# tac_sgcp register map
Vendor: Texas Instruments
Peripheral module from a debugger description file (folder Keystone2).
Registers are 32-bit, read-write, no defined reset value unless marked. A register's access mark holds for its fields unless they carry their own. Offsets are as the file gives them; lines under a group give offsets from that group; [hi:lo] are bit positions; {n}, {i} and the like mark numbered series; 'fields as' and 'values as' point back to an identical list; <NAME> marks a mode.

## TAC_SGCP
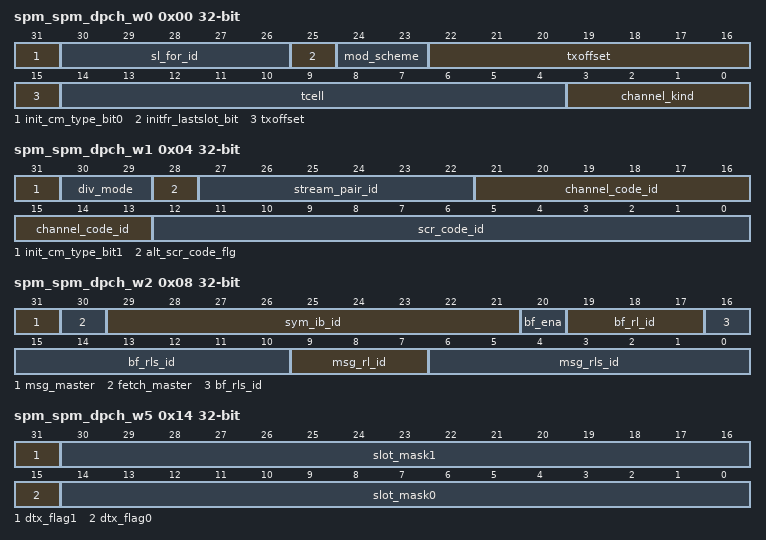
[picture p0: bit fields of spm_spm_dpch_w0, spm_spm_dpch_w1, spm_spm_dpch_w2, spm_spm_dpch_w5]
0x00 spm_spm_dpch_w0 — (1 of 512, stride 32)
  [31] init_cm_type_bit0, [30:26] sl_for_id, [25] initfr_lastslot_bit, [24:23] mod_scheme, [22:15] txoffset, [14:4] tcell, [3:0] channel_kind
0x04 spm_spm_dpch_w1 — (1 of 512, stride 32)
  [31] init_cm_type_bit1, [30:29] div_mode, [28] alt_scr_code_flg, [27:22] stream_pair_id, [21:13] channel_code_id, [12:0] scr_code_id
0x08 spm_spm_dpch_w2 — (1 of 512, stride 32)
  [31] msg_master, [30] fetch_master, [29:21] sym_ib_id, [20] bf_ena, [19:17] bf_rl_id, [16:10] bf_rls_id, [9:7] msg_rl_id, [6:0] msg_rls_id
0x0C spm_spm_dpch_w3 — (1 of 512, stride 32)
  [31:0] even_frame_ptr
0x10 spm_spm_dpch_w4 — (1 of 512, stride 32)
  [31:0] odd_frame_ptr
0x14 spm_spm_dpch_w5 — (1 of 512, stride 32)
  [31] dtx_flag1, [30:16] slot_mask1, [15] dtx_flag0, [14:0] slot_mask0
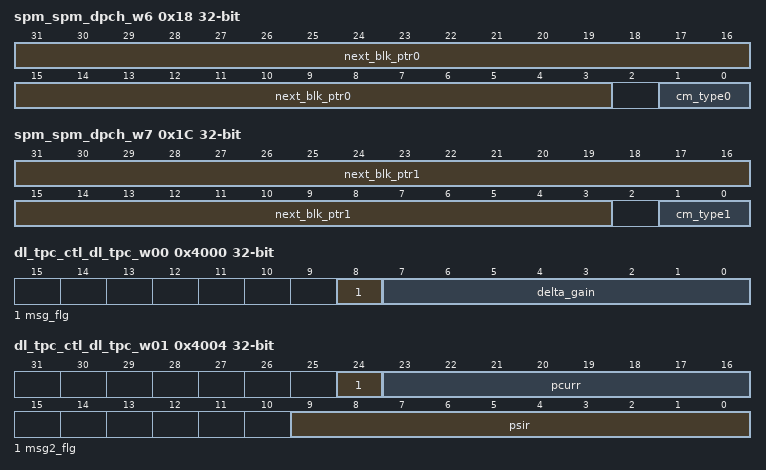
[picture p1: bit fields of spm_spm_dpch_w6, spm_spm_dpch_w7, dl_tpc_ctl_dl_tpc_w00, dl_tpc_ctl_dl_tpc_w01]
0x18 spm_spm_dpch_w6 — (1 of 512, stride 32)
  [31:3] next_blk_ptr0, [1:0] cm_type0
0x1C spm_spm_dpch_w7 — (1 of 512, stride 32)
  [31:3] next_blk_ptr1, [1:0] cm_type1
0x4000 dl_tpc_ctl_dl_tpc_w00 — (1 of 128, stride 128)
  [8] msg_flg, [7:0] delta_gain
0x4004 dl_tpc_ctl_dl_tpc_w01 — (1 of 128, stride 128)
  [24] msg2_flg, [23:16] pcurr, [9:0] psir
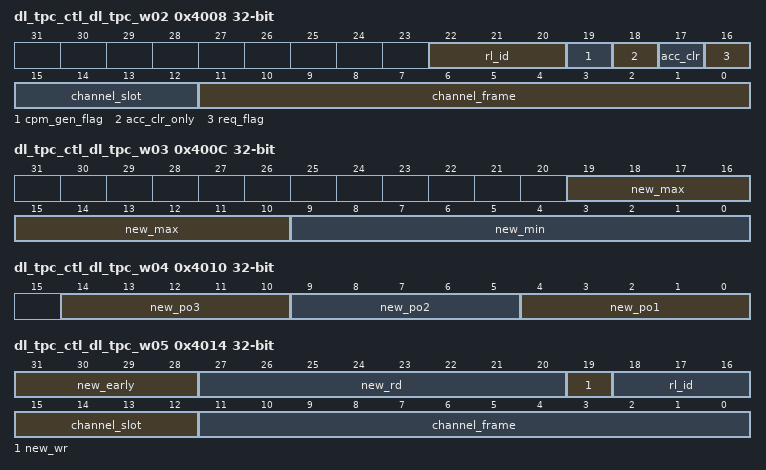
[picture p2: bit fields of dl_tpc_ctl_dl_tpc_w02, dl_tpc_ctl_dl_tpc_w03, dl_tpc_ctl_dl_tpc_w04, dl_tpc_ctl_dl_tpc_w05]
0x4008 dl_tpc_ctl_dl_tpc_w02 — (1 of 128, stride 128)
  [22:20] rl_id, [19] cpm_gen_flag, [18] acc_clr_only, [17] acc_clr, [16] req_flag, [15:12] channel_slot, [11:0] channel_frame
0x400C dl_tpc_ctl_dl_tpc_w03 — (1 of 128, stride 128)
  [19:10] new_max, [9:0] new_min
0x4010 dl_tpc_ctl_dl_tpc_w04 — (1 of 128, stride 128)
  [14:10] new_po3, [9:5] new_po2, [4:0] new_po1
0x4014 dl_tpc_ctl_dl_tpc_w05 — (1 of 128, stride 128)
  [31:28] new_early, [27:20] new_rd, [19] new_wr, [18:16] rl_id, [15:12] channel_slot, [11:0] channel_frame
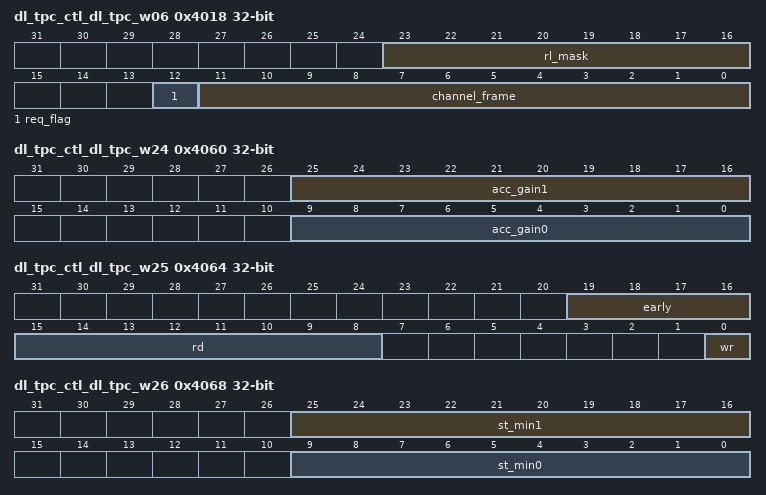
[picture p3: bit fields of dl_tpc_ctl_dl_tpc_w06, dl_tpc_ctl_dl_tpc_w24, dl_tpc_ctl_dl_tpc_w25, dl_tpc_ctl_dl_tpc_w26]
0x4018 dl_tpc_ctl_dl_tpc_w06 — (1 of 128, stride 128)
  [23:16] rl_mask, [12] req_flag, [11:0] channel_frame
0x401C dl_tpc_ctl_dl_tpc_w07 — (1 of 128, stride 128)
  [23:15] miss_counter
0x4020 dl_tpc_ctl_dl_tpc_w08 — (1 of 128, stride 128)
  [9:0] new_init0
{0x4000+4i} dl_tpc_ctl_dl_tpc_w{i} (i=9..15) — (1 of 128, stride 128)
  [9:0] new_init{i-8}
{0x4000+4i} dl_tpc_ctl_dl_tpc_w{i} (i=16..23) — (1 of 128, stride 128)
  [9:0] init{i-16}
0x4060 dl_tpc_ctl_dl_tpc_w24 — (1 of 128, stride 128)
  [25:16] acc_gain1, [9:0] acc_gain0
0x4064 dl_tpc_ctl_dl_tpc_w25 — (1 of 128, stride 128)
  [19:16] early, [15:8] rd, [0] wr
0x4068 dl_tpc_ctl_dl_tpc_w26 — (1 of 128, stride 128)
  [25:16] st_min1, [9:0] st_min0
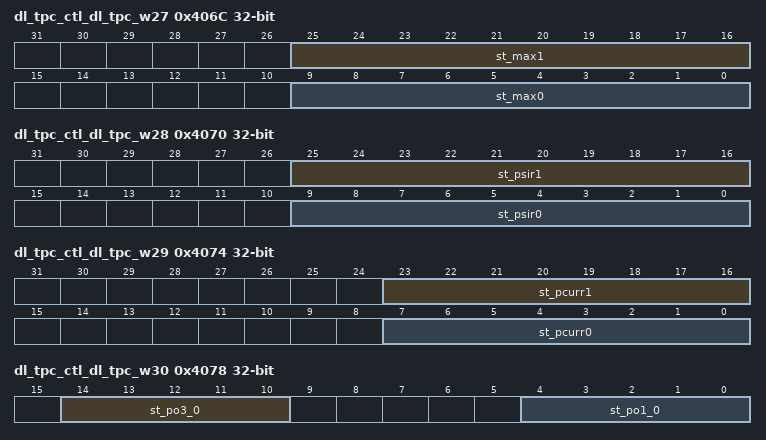
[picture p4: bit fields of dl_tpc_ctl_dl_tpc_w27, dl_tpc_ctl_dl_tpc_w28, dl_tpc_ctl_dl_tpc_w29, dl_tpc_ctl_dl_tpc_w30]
0x406C dl_tpc_ctl_dl_tpc_w27 — (1 of 128, stride 128)
  [25:16] st_max1, [9:0] st_max0
0x4070 dl_tpc_ctl_dl_tpc_w28 — (1 of 128, stride 128)
  [25:16] st_psir1, [9:0] st_psir0
0x4074 dl_tpc_ctl_dl_tpc_w29 — (1 of 128, stride 128)
  [23:16] st_pcurr1, [7:0] st_pcurr0
0x4078 dl_tpc_ctl_dl_tpc_w30 — (1 of 128, stride 128)
  [14:10] st_po3_0, [4:0] st_po1_0
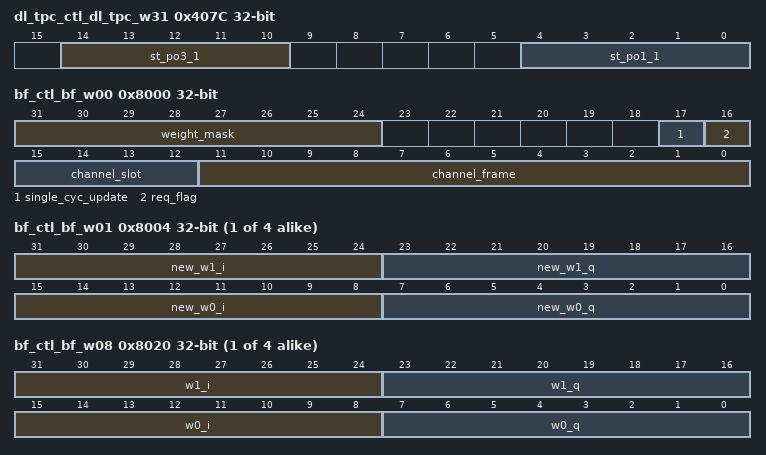
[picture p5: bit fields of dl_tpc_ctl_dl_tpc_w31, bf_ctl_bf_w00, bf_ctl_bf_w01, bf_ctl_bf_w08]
0x407C dl_tpc_ctl_dl_tpc_w31 — (1 of 128, stride 128)
  [14:10] st_po3_1, [4:0] st_po1_1
0x8000 bf_ctl_bf_w00 — (1 of 128, stride 64)
  [31:24] weight_mask, [17] single_cyc_update, [16] req_flag, [15:12] channel_slot, [11:0] channel_frame
{0x8000+4i} bf_ctl_bf_w{i:02} (i=1..4) — (1 of 128, stride 64)
  [31:24] new_w{2i-1}_i, [23:16] new_w{2i-1}_q, [15:8] new_w{2i-2}_i, [7:0] new_w{2i-2}_q
{0x8000+4i} bf_ctl_bf_w{i:02} (i=8..11) — (1 of 128, stride 64)
  [31:24] w{2i-15}_i, [23:16] w{2i-15}_q, [15:8] w{2i-16}_i, [7:0] w{2i-16}_q
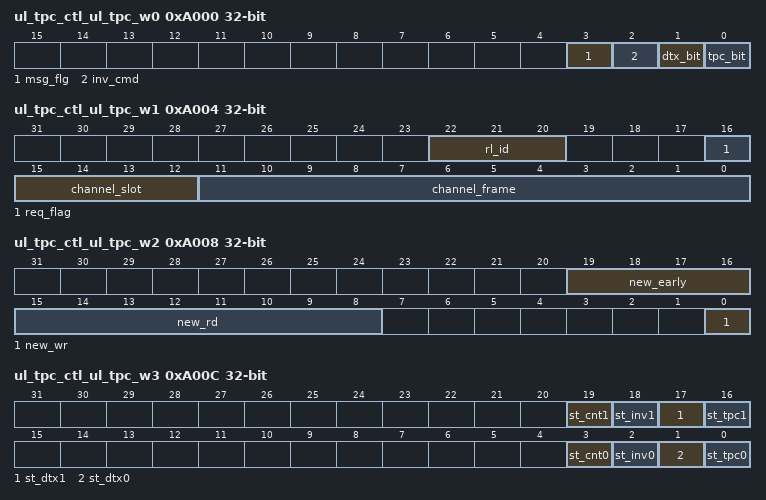
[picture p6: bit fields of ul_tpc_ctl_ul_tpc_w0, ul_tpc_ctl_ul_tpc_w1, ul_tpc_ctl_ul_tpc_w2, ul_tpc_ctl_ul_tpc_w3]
0xA000 ul_tpc_ctl_ul_tpc_w0 — (1 of 128, stride 32)
  [3] msg_flg, [2] inv_cmd, [1] dtx_bit, [0] tpc_bit
0xA004 ul_tpc_ctl_ul_tpc_w1 — (1 of 128, stride 32)
  [22:20] rl_id, [16] req_flag, [15:12] channel_slot, [11:0] channel_frame
0xA008 ul_tpc_ctl_ul_tpc_w2 — (1 of 128, stride 32)
  [19:16] new_early, [15:8] new_rd, [0] new_wr
0xA00C ul_tpc_ctl_ul_tpc_w3 — (1 of 128, stride 32)
  [19] st_cnt1, [18] st_inv1, [17] st_dtx1, [16] st_tpc1, [3] st_cnt0, [2] st_inv0, [1] st_dtx0, [0] st_tpc0
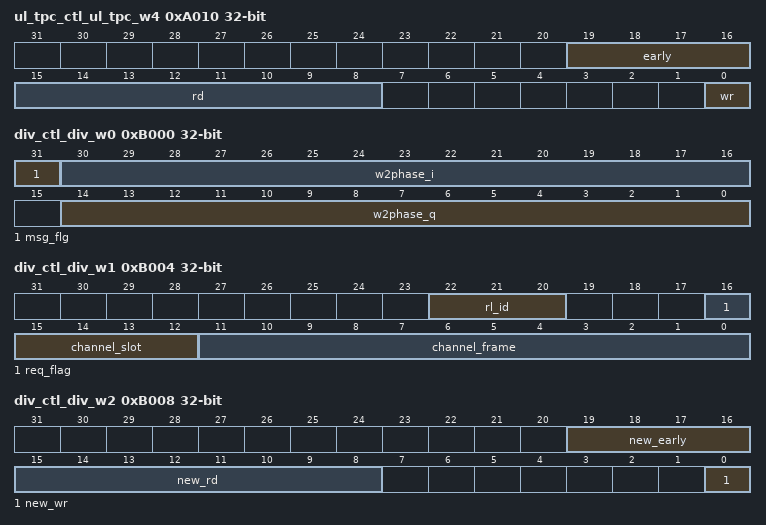
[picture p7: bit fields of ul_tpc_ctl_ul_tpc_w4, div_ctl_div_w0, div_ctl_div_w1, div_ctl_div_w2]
0xA010 ul_tpc_ctl_ul_tpc_w4 — (1 of 128, stride 32)
  [19:16] early, [15:8] rd, [0] wr
0xA01C ul_tpc_ctl_ul_tpc_w7 — (1 of 128, stride 32)
  [23:15] miss_counter
0xB000 div_ctl_div_w0 — (1 of 128, stride 32)
  [31] msg_flg, [30:16] w2phase_i, [14:0] w2phase_q
0xB004 div_ctl_div_w1 — (1 of 128, stride 32)
  fields as ul_tpc_ctl_ul_tpc_w1
0xB008 div_ctl_div_w2 — (1 of 128, stride 32)
  [19:16] new_early, [15:8] new_rd, [0] new_wr
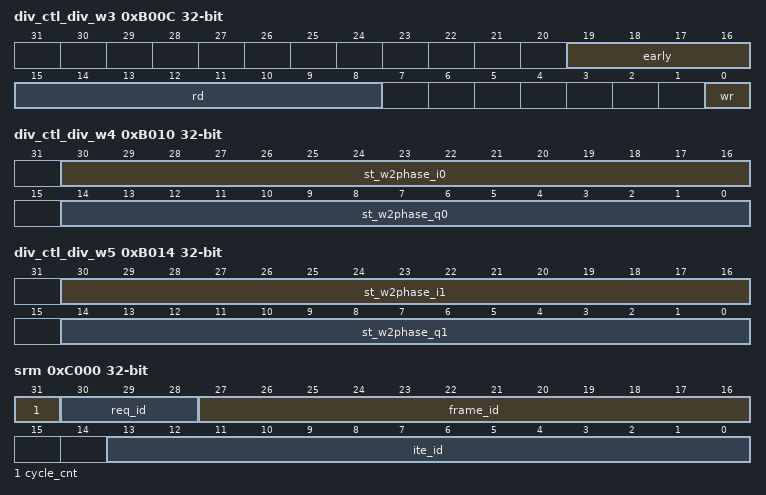
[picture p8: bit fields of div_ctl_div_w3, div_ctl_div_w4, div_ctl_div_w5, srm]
0xB00C div_ctl_div_w3 — (1 of 128, stride 32)
  [19:16] early, [15:8] rd, [0] wr
0xB010 div_ctl_div_w4 — (1 of 128, stride 32)
  [30:16] st_w2phase_i0, [14:0] st_w2phase_q0
0xB014 div_ctl_div_w5 — (1 of 128, stride 32)
  [30:16] st_w2phase_i1, [14:0] st_w2phase_q1
0xB01C div_ctl_div_w7 — (1 of 128, stride 32)
  [23:15] miss_counter
0xC000 srm — (1 of 512, stride 4)
  [31] cycle_cnt, [30:28] req_id, [27:16] frame_id, [13:0] ite_id
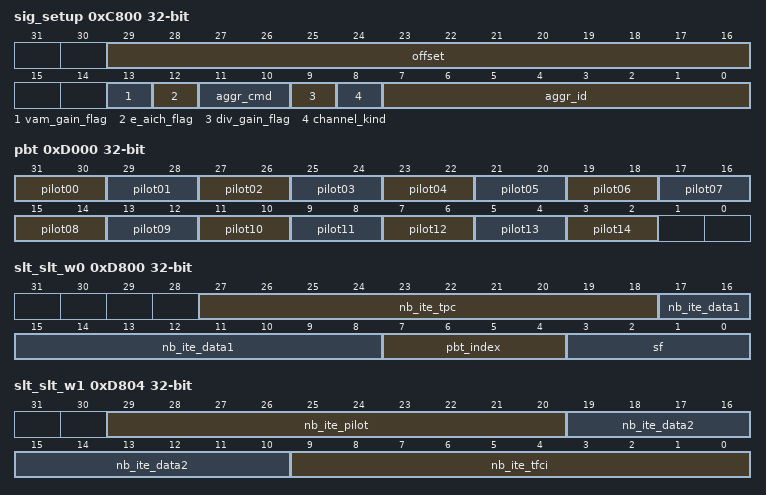
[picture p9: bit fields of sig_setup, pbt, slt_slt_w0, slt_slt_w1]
0xC800 sig_setup — (1 of 384, stride 4)
  [29:16] offset, [13] vam_gain_flag, [12] e_aich_flag, [11:10] aggr_cmd, [9] div_gain_flag, [8] channel_kind, [7:0] aggr_id
0xD000 pbt — (1 of 300, stride 4)
  [31-2n:30-2n] pilot{n:02} (n=0..14)
0xD800 slt_slt_w0 — (1 of 128, stride 8)
  [27:18] nb_ite_tpc, [17:8] nb_ite_data1, [7:4] pbt_index, [3:0] sf
0xD804 slt_slt_w1 — (1 of 128, stride 8)
  [29:20] nb_ite_pilot, [19:10] nb_ite_data2, [9:0] nb_ite_tfci
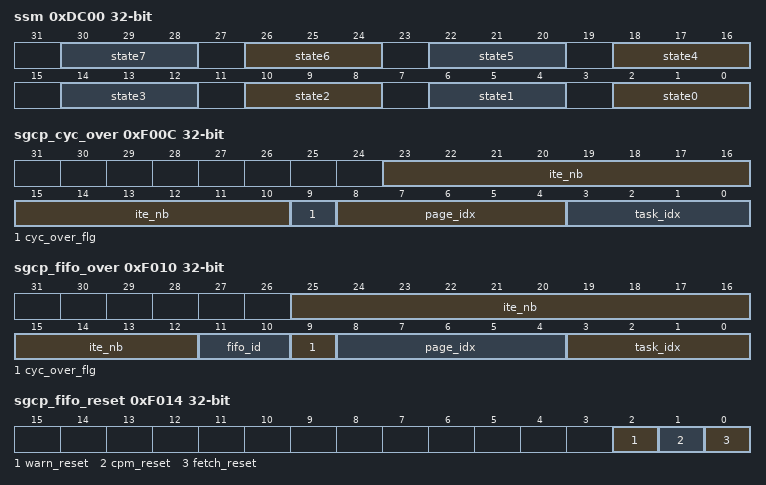
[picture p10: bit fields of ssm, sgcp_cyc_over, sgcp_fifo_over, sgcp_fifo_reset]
0xDC00 ssm — (1 of 64, stride 4)
  [4n+2:4n] state{n} (n=0..7)
0xF000 sgcp_seq_ena
  [0] enable
0xF004 sgcp_seq_act
  [8:0] act_count
0xF008 sgcp_seq_cyc
  [8:0] seq_count
0xF00C sgcp_cyc_over
  [23:10] ite_nb, [9] cyc_over_flg, [8:4] page_idx, [3:0] task_idx
0xF010 sgcp_fifo_over
  [25:12] ite_nb, [11:10] fifo_id, [9] cyc_over_flg, [8:4] page_idx, [3:0] task_idx
0xF014 sgcp_fifo_reset
  [2] warn_reset, [1] cpm_reset, [0] fetch_reset
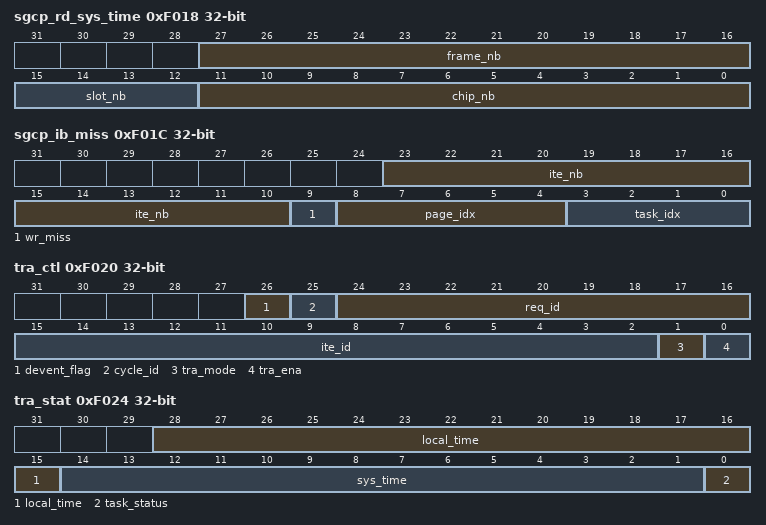
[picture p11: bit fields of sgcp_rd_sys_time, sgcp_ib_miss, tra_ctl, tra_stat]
0xF018 sgcp_rd_sys_time
  [27:16] frame_nb, [15:12] slot_nb, [11:0] chip_nb
0xF01C sgcp_ib_miss
  [23:10] ite_nb, [9] wr_miss, [8:4] page_idx, [3:0] task_idx
0xF020 tra_ctl
  [26] devent_flag, [25] cycle_id, [24:16] req_id, [15:2] ite_id, [1] tra_mode, [0] tra_ena
0xF024 tra_stat
  [28:15] local_time, [14:1] sys_time, [0] task_status
0xF028 tra_ina — (1 of 2, stride 4)
  [31:0] word
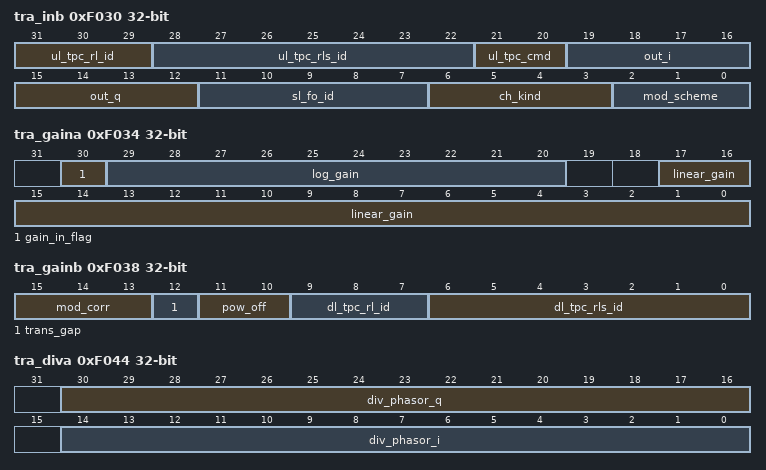
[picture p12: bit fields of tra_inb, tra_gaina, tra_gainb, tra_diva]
0xF030 tra_inb
  [31:29] ul_tpc_rl_id, [28:22] ul_tpc_rls_id, [21:20] ul_tpc_cmd, [19:16] out_i, [15:12] out_q, [11:7] sl_fo_id, [6:3] ch_kind, [2:0] mod_scheme
0xF034 tra_gaina
  [30] gain_in_flag, [29:20] log_gain, [17:0] linear_gain
0xF038 tra_gainb
  [15:13] mod_corr, [12] trans_gap, [11:10] pow_off, [9:7] dl_tpc_rl_id, [6:0] dl_tpc_rls_id
0xF03C tra_gaincd — (1 of 2, stride 4)
  [22:0] gain_out
0xF044 tra_diva
  [30:16] div_phasor_q, [14:0] div_phasor_i
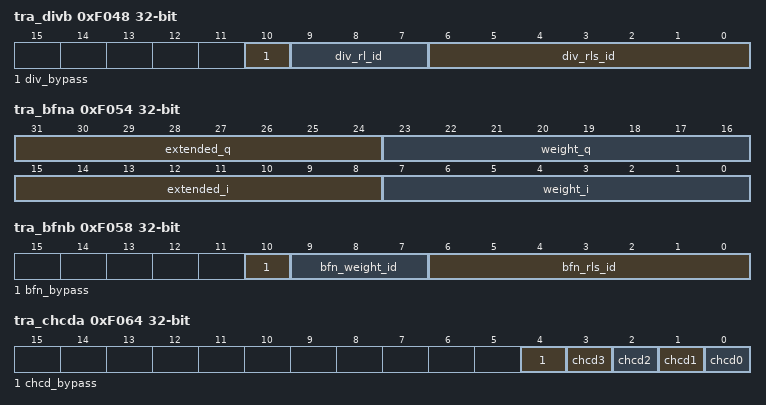
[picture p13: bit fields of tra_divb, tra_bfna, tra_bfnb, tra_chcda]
0xF048 tra_divb
  [10] div_bypass, [9:7] div_rl_id, [6:0] div_rls_id
0xF04C tra_divcd — (1 of 2, stride 4)
  [22:0] div_out
0xF054 tra_bfna
  [31:24] extended_q, [23:16] weight_q, [15:8] extended_i, [7:0] weight_i
0xF058 tra_bfnb
  [10] bfn_bypass, [9:7] bfn_weight_id, [6:0] bfn_rls_id
0xF05C tra_bfncd — (1 of 2, stride 4)
  [22:0] bfn_out
0xF064 tra_chcda
  [4] chcd_bypass, [n] chcd{n} (n=0..3)
0xF068 tra_chcdbc — (1 of 2, stride 4)
  [22:0] chcd_out
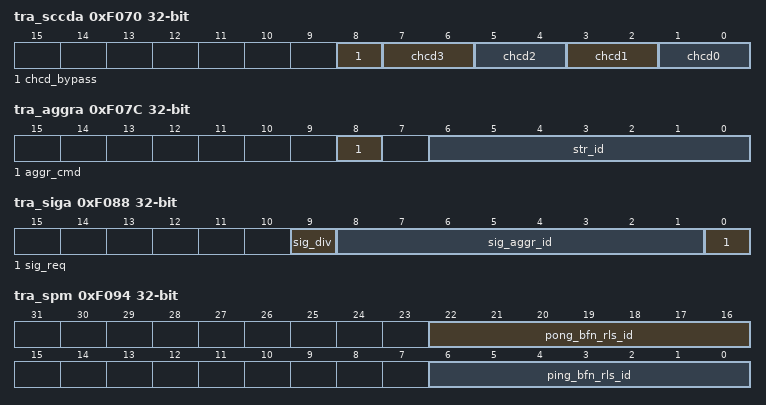
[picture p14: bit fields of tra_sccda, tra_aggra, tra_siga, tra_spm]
0xF070 tra_sccda
  [8] chcd_bypass, [2n+1:2n] chcd{n} (n=0..3)
0xF074 tra_sccdbc — (1 of 2, stride 4)
  [22:0] sccd_out
0xF07C tra_aggra
  [8] aggr_cmd, [6:0] str_id
0xF080 tra_aggrbc — (1 of 2, stride 4)
  [23:0] aggr_out
0xF088 tra_siga
  [9] sig_div, [8:1] sig_aggr_id, [0] sig_req
0xF08C tra_sigbc — (1 of 2, stride 4)
  [21:0] sig_out
0xF094 tra_spm — (1 of 9, stride 4)
  [22:16] pong_bfn_rls_id, [6:0] ping_bfn_rls_id
0xF0FC spm_word_9
  [31:0] word
0xF100 pat
  [n] page_{n} (n=0..31)
0xF104 sig_page_en
  [n] page_{n} (n=0..23)
0xF108 head_fetch
  [4:0] head_latency
0xF10C data_fetch
  [4:0] data_latency
0xF200 ss2m — (1 of 16, stride 4)
  [n] state{n} (n=0..31)
0xF800 ftq_curr_lvl
  [9:0] curr_lvl
0xF804 ftq_wtmk_lvl
  [9:0] watermark
0xF808 ctq_curr_lvl
  [7:0] curr_lvl
0xF80C ctq_wtmk_lvl
  [7:0] watermark
0xF810 wtq_curr_lvl
  [7:0] curr_lvl
0xF814 wtq_wtmk_lvl
  [7:0] watermark
